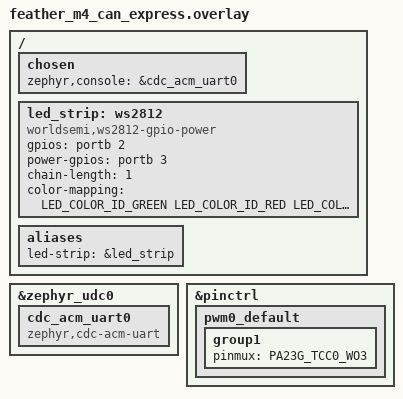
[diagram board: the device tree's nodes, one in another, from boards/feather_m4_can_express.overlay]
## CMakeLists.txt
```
# SPDX-License-Identifier: Apache-2.0

cmake_minimum_required(VERSION 3.20.0)

# Add custom board directory (for feather_m4_can_express)
list(APPEND BOARD_ROOT ${CMAKE_CURRENT_SOURCE_DIR}/..)

# Add custom DTS bindings directory
list(APPEND DTS_ROOT ${CMAKE_CURRENT_SOURCE_DIR})

find_package(Zephyr REQUIRED HINTS $ENV{ZEPHYR_BASE})
project(m4_express_blinky)

target_sources(app PRIVATE
    src/main.c
    src/led.c
    src/canrx.c
    src/canwork.c
    src/pwm.c
    src/ws2812_gpio_sam0.c
)
```

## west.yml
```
# SPDX-License-Identifier: Apache-2.0
#
# West manifest for M4 Express NeoPixel Blinky
# This makes the project a self-contained Zephyr application

manifest:
  remotes:
    - name: zephyrproject-rtos
      url-base: https://github.com/zephyrproject-rtos

  projects:
    - name: zephyr
      remote: zephyrproject-rtos
      revision: main
      import: true

  self:
    path: app
```

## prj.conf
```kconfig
# Logging (immediate mode for USB CDC console)
CONFIG_LOG=y
CONFIG_LOG_MODE_IMMEDIATE=y

# LED Strip driver
CONFIG_LED_STRIP=y
CONFIG_LED_STRIP_LOG_LEVEL_DBG=y

# USB CDC ACM for console
CONFIG_USB_DEVICE_STACK=y
CONFIG_USB_CDC_ACM=y
CONFIG_CONSOLE=y
CONFIG_UART_CONSOLE=y

# USB device identification
CONFIG_USB_DEVICE_PRODUCT="Feather M4 CAN"
CONFIG_USB_DEVICE_VID=0x239A
CONFIG_USB_DEVICE_PID=0x0022

# CAN bus
CONFIG_CAN=y

# PWM
CONFIG_PWM=y

# Increase log buffer for debugging
CONFIG_LOG_BUFFER_SIZE=2048
```

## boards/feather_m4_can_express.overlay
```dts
/*
 * Device tree overlay for Adafruit Feather M4 Express CAN
 * NeoPixel (RGBW) configuration
 *
 * SPDX-License-Identifier: Apache-2.0
 */

#include <zephyr/dt-bindings/led/led.h>
#include <dt-bindings/pinctrl/same51j-pinctrl.h>

/ {
    chosen {
        zephyr,console = &cdc_acm_uart0;
    };

    led_strip: ws2812 {
        compatible = "worldsemi,ws2812-gpio-power";

        /* NeoPixel data pin: PB02 */
        gpios = <&portb 2 0>;

        /* NeoPixel power enable pin: PB03 (set HIGH to power the NeoPixel) */
        power-gpios = <&portb 3 0>;

        chain-length = <1>;

        /* GRBW order for RGBW NeoPixels */
        color-mapping = <LED_COLOR_ID_GREEN
                         LED_COLOR_ID_RED
                         LED_COLOR_ID_BLUE
                         LED_COLOR_ID_WHITE>;
    };

    aliases {
        led-strip = &led_strip;
    };
};

&zephyr_udc0 {
    cdc_acm_uart0: cdc_acm_uart0 {
        compatible = "zephyr,cdc-acm-uart";
    };
};

/* Override PWM0 pinctrl to use LED pin PA23 (TCC0_WO3) */
&pinctrl {
    pwm0_default: pwm0_default {
        group1 {
            pinmux = <PA23G_TCC0_WO3>;
        };
    };
};
```

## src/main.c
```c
/*
 * Main - USB initialization and system startup
 *
 * Adafruit Feather M4 Express CAN Demo
 * - LED thread: cycles NeoPixel through colors
 * - CAN RX thread: receives CAN frames and prints to console
 *
 * SPDX-License-Identifier: Apache-2.0
 */

#include <errno.h>

#define LOG_LEVEL 4
#include <zephyr/logging/log.h>
LOG_MODULE_REGISTER(main);

#include <zephyr/kernel.h>
#include <zephyr/device.h>
#include <zephyr/usb/usb_device.h>

int main(void)
{
	int rc;

	/* Enable USB */
	const struct device *usb_dev = DEVICE_DT_GET_ONE(zephyr_cdc_acm_uart);

	if (!device_is_ready(usb_dev)) {
		LOG_ERR("USB device not ready");
		return 0;
	}

	rc = usb_enable(NULL);
	if (rc != 0 && rc != -EALREADY) {
		LOG_ERR("Failed to enable USB: %d", rc);
		return 0;
	}

	LOG_INF("=== Feather M4 CAN Express Demo ===");
	LOG_INF("LED thread: NeoPixel color cycling");
	LOG_INF("CAN RX thread: listening for CAN frames");
	LOG_INF("CAN work thread: processing received frames");
	LOG_INF("PWM0 thread: PA23/D13 LED duty cycle sweep");
	LOG_INF("PWM1 thread: PA5 duty cycle sweep");

	return 0;
}
```

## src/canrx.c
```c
/*
 * CAN RX Thread - Receives CAN frames and queues for processing
 *
 * SPDX-License-Identifier: Apache-2.0
 */

#define LOG_LEVEL 4
#include <zephyr/logging/log.h>
LOG_MODULE_REGISTER(canrx);

#include <zephyr/kernel.h>
#include <zephyr/device.h>
#include <zephyr/drivers/can.h>
#include <zephyr/drivers/gpio.h>

#include "canwork.h"

/* Thread stack size and priority */
#define CANRX_THREAD_STACK_SIZE 1024
#define CANRX_THREAD_PRIORITY   5

/* CAN device from devicetree */
static const struct device *const can_dev = DEVICE_DT_GET(DT_CHOSEN(zephyr_canbus));

/* CAN transceiver control GPIOs */
static const struct gpio_dt_spec boost_enable = GPIO_DT_SPEC_GET(DT_NODELABEL(boost_enable), gpios);
static const struct gpio_dt_spec can_standby = GPIO_DT_SPEC_GET(DT_NODELABEL(can_standby), gpios);

/* Message queue for frames from CAN driver ISR */
CAN_MSGQ_DEFINE(can_rx_msgq, 16);

/* Statistics */
static volatile uint32_t frames_received;

static int can_transceiver_enable(void)
{
	int ret;

	/* Configure boost enable GPIO (HIGH to enable 5V for CAN bus) */
	if (!gpio_is_ready_dt(&boost_enable)) {
		LOG_ERR("Boost enable GPIO not ready");
		return -ENODEV;
	}


	/* Configure CAN standby GPIO (LOW to enable transceiver) */
	if (!gpio_is_ready_dt(&can_standby)) {
		LOG_ERR("CAN standby GPIO not ready");
		return -ENODEV;
	}

	ret = gpio_pin_configure_dt(&can_standby, GPIO_OUTPUT_LOW);
	if (ret < 0) {
		LOG_ERR("Failed to configure CAN standby: %d", ret);
		return ret;
	}

	ret = gpio_pin_configure_dt(&boost_enable, GPIO_OUTPUT_HIGH);
	if (ret < 0) {
		LOG_ERR("Failed to configure boost enable: %d", ret);
		return ret;
	}

	LOG_INF("CAN transceiver enabled");
	return 0;
}

/*
 * CAN RX thread - receives frames and queues for processing
 */
static void canrx_thread_entry(void *p1, void *p2, void *p3)
{
	ARG_UNUSED(p1);
	ARG_UNUSED(p2);
	ARG_UNUSED(p3);

	struct can_frame frame;
	struct can_filter filter = {
		.flags = 0,
		.id = 0,
		.mask = 0,  /* Accept all IDs */
	};
	int ret;
	int filter_id;

	LOG_INF("CAN RX thread started");

	if (!device_is_ready(can_dev)) {
		LOG_ERR("CAN device not ready");
		return;
	}

	/* Enable the CAN transceiver */
	ret = can_transceiver_enable();
	if (ret < 0) {
		LOG_ERR("Failed to enable CAN transceiver");
		return;
	}

	/* Set CAN bitrate to 500 kbit/s */
	ret = can_set_bitrate(can_dev, 500000);
	if (ret < 0) {
		LOG_ERR("Failed to set CAN bitrate: %d", ret);
		return;
	}

	/* Set listen-only mode (passive - no ACKs or transmissions) */
	ret = can_set_mode(can_dev, CAN_MODE_LISTENONLY);
	if (ret < 0) {
		LOG_ERR("Failed to set CAN mode: %d", ret);
		return;
	}

	/* Start the CAN controller */
	ret = can_start(can_dev);
	if (ret < 0) {
		LOG_ERR("Failed to start CAN: %d", ret);
		return;
	}

	/* Add filter to receive all frames into rx queue */
	filter_id = can_add_rx_filter_msgq(can_dev, &can_rx_msgq, &filter);
	if (filter_id < 0) {
		LOG_ERR("Failed to add CAN filter: %d", filter_id);
		return;
	}

	LOG_INF("CAN initialized, listening for frames...");

	while (1) {
		/* Wait for a frame from the driver */
		ret = k_msgq_get(&can_rx_msgq, &frame, K_FOREVER);
		if (ret == 0) {
			frames_received++;

			/* Submit for processing */
			canwork_submit(&frame);
		}
	}
}

/* Define CAN RX thread statically */
K_THREAD_DEFINE(canrx_thread, CANRX_THREAD_STACK_SIZE,
		canrx_thread_entry, NULL, NULL, NULL,
		CANRX_THREAD_PRIORITY, 0, 0);
```

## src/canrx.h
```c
/*
 * CAN RX Thread Header
 *
 * SPDX-License-Identifier: Apache-2.0
 */

#ifndef CANRX_H_
#define CANRX_H_

/*
 * CAN RX thread is defined statically with K_THREAD_DEFINE and starts
 * automatically at boot. No explicit API needed.
 */

#endif /* CANRX_H_ */
```

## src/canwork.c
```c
/*
 * CAN Work Thread - Processes received CAN frames
 *
 * SPDX-License-Identifier: Apache-2.0
 */

#define LOG_LEVEL 4
#include <zephyr/logging/log.h>
LOG_MODULE_REGISTER(canwork);

#include <zephyr/kernel.h>
#include <zephyr/drivers/can.h>
#include <zephyr/sys/atomic.h>

#include "canwork.h"

/* Thread stack size and priority */
#define CANWORK_THREAD_STACK_SIZE 1024
#define CANWORK_THREAD_PRIORITY   6

/* Work queue depth - frames dropped if full */
#define CAN_WORK_QUEUE_DEPTH 16

/* Message queue for canrx -> canwork communication */
K_MSGQ_DEFINE(can_work_msgq, sizeof(struct can_frame), CAN_WORK_QUEUE_DEPTH, 4);

/* Statistics (atomic for thread-safe access) */
static atomic_t frames_processed;
static atomic_t frames_dropped;

int canwork_submit(const struct can_frame *frame)
{
	int ret;

	ret = k_msgq_put(&can_work_msgq, frame, K_NO_WAIT);
	if (ret != 0) {
		atomic_inc(&frames_dropped);
		LOG_WRN("Work queue full, frame dropped (total dropped: %ld)",
			atomic_get(&frames_dropped));
		return -ENOMSG;
	}

	return 0;
}

uint32_t canwork_get_frames_processed(void)
{
	return (uint32_t)atomic_get(&frames_processed);
}

/*
 * CAN work thread - processes queued frames
 */
static void canwork_thread_entry(void *p1, void *p2, void *p3)
{
	ARG_UNUSED(p1);
	ARG_UNUSED(p2);
	ARG_UNUSED(p3);

	struct can_frame frame;
	int ret;

	LOG_INF("CAN work thread started");

	while (1) {
		/* Wait for a frame to process */
		ret = k_msgq_get(&can_work_msgq, &frame, K_FOREVER);
		if (ret == 0) {
			atomic_val_t count = atomic_inc(&frames_processed) + 1;

			/* Only log every 100th frame to avoid USB bottleneck */
			if ((count % 3) == 1) {
				/* Print the frame */
				if (frame.flags & CAN_FRAME_IDE) {
					LOG_INF("CAN RX: ID=0x%08x [%d] (total: %ld)",
						frame.id, frame.dlc, count);
				} else {
					LOG_INF("CAN RX: ID=0x%03x [%d] (total: %ld)",
						frame.id, frame.dlc, count);
				}
			}
		}
	}
}

/* Define CAN work thread statically */
K_THREAD_DEFINE(canwork_thread, CANWORK_THREAD_STACK_SIZE,
		canwork_thread_entry, NULL, NULL, NULL,
		CANWORK_THREAD_PRIORITY, 0, 0);
```

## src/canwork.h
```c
/*
 * CAN Work Thread Header
 *
 * SPDX-License-Identifier: Apache-2.0
 */

#ifndef CANWORK_H_
#define CANWORK_H_

#include <zephyr/kernel.h>
#include <zephyr/drivers/can.h>

/* Work queue for CAN frames to be processed */
extern struct k_msgq can_work_msgq;

/*
 * Submit a CAN frame for processing.
 * Non-blocking - returns 0 on success, -ENOMSG if queue is full (frame dropped).
 */
int canwork_submit(const struct can_frame *frame);

/*
 * Get the number of CAN frames processed.
 */
uint32_t canwork_get_frames_processed(void);

#endif /* CANWORK_H_ */
```

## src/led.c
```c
/*
 * LED Thread - NeoPixel color cycling based on CAN frames
 *
 * SPDX-License-Identifier: Apache-2.0
 */

#include <string.h>

#define LOG_LEVEL 4
#include <zephyr/logging/log.h>
LOG_MODULE_REGISTER(led);

#include <zephyr/kernel.h>
#include <zephyr/drivers/led_strip.h>
#include <zephyr/device.h>
#include <zephyr/sys/util.h>

#include "canwork.h"

#define STRIP_NUM_PIXELS 1

/* LED thread stack size and priority (lowest priority) */
#define LED_THREAD_STACK_SIZE 1024
#define LED_THREAD_PRIORITY   K_LOWEST_APPLICATION_THREAD_PRIO

#define RGB(_r, _g, _b) { .r = (_r), .g = (_g), .b = (_b) }

static const struct led_rgb colors[] = {
	RGB(0x20, 0x00, 0x00), /* red */
	RGB(0x00, 0x20, 0x00), /* green */
	RGB(0x00, 0x00, 0x20), /* blue */
	RGB(0x20, 0x20, 0x20), /* white (RGB mix) */
};

static struct led_rgb pixels[STRIP_NUM_PIXELS];

static const struct device *const strip = DEVICE_DT_GET(DT_NODELABEL(led_strip));

/*
 * LED flashing thread - runs at lowest priority
 * This thread handles the LED color cycling independently
 */
static void led_thread_entry(void *p1, void *p2, void *p3)
{
	ARG_UNUSED(p1);
	ARG_UNUSED(p2);
	ARG_UNUSED(p3);

	size_t color = 0;
	int rc;

	LOG_INF("LED thread started (priority: %d)", LED_THREAD_PRIORITY);

	if (!device_is_ready(strip)) {
		LOG_ERR("LED strip device %s is NOT ready", strip->name);
		return;
	}

	LOG_INF("LED strip device is ready");
	LOG_INF("Starting color cycle based on CAN frames received");

	while (1) {
		/* Select color based on CAN frames received mod 4 */
		color = canwork_get_frames_processed() % ARRAY_SIZE(colors);

		memset(&pixels, 0x00, sizeof(pixels));
		memcpy(&pixels[0], &colors[color], sizeof(struct led_rgb));

		rc = led_strip_update_rgb(strip, pixels, STRIP_NUM_PIXELS);
		if (rc) {
			LOG_ERR("led_strip_update_rgb failed: %d", rc);
		}

		k_sleep(K_MSEC(50));
	}
}

/* Define LED thread statically - starts automatically at boot */
K_THREAD_DEFINE(led_thread, LED_THREAD_STACK_SIZE,
		led_thread_entry, NULL, NULL, NULL,
		LED_THREAD_PRIORITY, 0, 0);
```

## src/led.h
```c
/*
 * LED Thread Header
 *
 * SPDX-License-Identifier: Apache-2.0
 */

#ifndef LED_H_
#define LED_H_

/*
 * LED thread is defined statically with K_THREAD_DEFINE and starts
 * automatically at boot. No explicit API needed.
 */

#endif /* LED_H_ */
```

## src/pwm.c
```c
/*
 * PWM Threads - Hardware PWM control on two pins
 *
 * PWM0: TCC0 channel 2 on PA22
 * PWM1: TC0 channel 1 on PA5
 *
 * Both cycle through 0%, 50%, 100% duty cycle (5 seconds each)
 *
 * SPDX-License-Identifier: Apache-2.0
 */

#define LOG_LEVEL 4
#include <zephyr/logging/log.h>
LOG_MODULE_REGISTER(pwm);

#include <zephyr/kernel.h>
#include <zephyr/device.h>
#include <zephyr/drivers/pwm.h>

/* PWM thread stack size and priority */
#define PWM_THREAD_STACK_SIZE 1024
#define PWM_THREAD_PRIORITY   8

/* PWM period (1 kHz = 1ms period) */
#define PWM_PERIOD_NS 1000000U

/* Duty cycle hold time */
#define DUTY_HOLD_MS 5000

/* PWM configuration structure - device resolved at runtime */
struct pwm_config {
	const char *dev_label;
	uint32_t channel;
	const char *name;
};

/* PWM configurations - device lookup done at runtime */
static const struct pwm_config pwm_configs[] = {
	{
		.dev_label = "pwm_0",  /* DT alias */
		.channel = 3,         /* TCC0_WO3 on PA23 (LED) */
		.name = "PWM0",
	},
	{
		.dev_label = "pwm_1",  /* DT alias */
		.channel = 1,         /* TC0_WO1 */
		.name = "PWM1",
	},
};

/* Duty cycle percentages to cycle through */
static const uint8_t duty_cycles[] = { 0, 50, 100 };

/*
 * PWM thread entry point - shared by both PWM threads
 * p1: index into pwm_configs
 */
static void pwm_thread_entry(void *p1, void *p2, void *p3)
{
	int cfg_idx = (int)(intptr_t)p1;
	ARG_UNUSED(p2);
	ARG_UNUSED(p3);

	const struct pwm_config *cfg = &pwm_configs[cfg_idx];
	const struct device *dev;
	size_t idx = 0;
	int ret;

	LOG_INF("%s thread started", cfg->name);

	/* Get PWM device at runtime */
	if (cfg_idx == 0) {
		dev = DEVICE_DT_GET(DT_ALIAS(pwm_0));
	} else {
		dev = DEVICE_DT_GET(DT_ALIAS(pwm_1));
	}

	if (dev == NULL) {
		LOG_ERR("%s: PWM device is NULL", cfg->name);
		return;
	}

	if (!device_is_ready(dev)) {
		LOG_ERR("%s: PWM device not ready", cfg->name);
		return;
	}

	LOG_INF("%s: PWM device ready (channel %u), period=%u ns",
		cfg->name, cfg->channel, PWM_PERIOD_NS);

	while (1) {
		uint8_t duty_pct = duty_cycles[idx];
		uint32_t pulse_ns = (PWM_PERIOD_NS * duty_pct) / 100;

		ret = pwm_set(dev, cfg->channel, PWM_PERIOD_NS, pulse_ns, 0);
		if (ret < 0) {
			LOG_ERR("%s: pwm_set failed: %d", cfg->name, ret);
		} else {
			LOG_INF("%s: duty=%3u%% (pulse=%u ns)",
				cfg->name, duty_pct, pulse_ns);
		}

		k_sleep(K_MSEC(DUTY_HOLD_MS));

		idx = (idx + 1) % ARRAY_SIZE(duty_cycles);
	}
}

/* Define PWM threads statically - delayed start (1000ms) to let system stabilize */
K_THREAD_DEFINE(pwm0_thread, PWM_THREAD_STACK_SIZE,
		pwm_thread_entry, (void *)0, NULL, NULL,
		PWM_THREAD_PRIORITY, 0, 1000);

/* TEMPORARILY DISABLED FOR DEBUGGING
K_THREAD_DEFINE(pwm1_thread, PWM_THREAD_STACK_SIZE,
		pwm_thread_entry, (void *)1, NULL, NULL,
		PWM_THREAD_PRIORITY, 0, 0);
*/
```

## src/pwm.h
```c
/*
 * PWM Threads Header
 *
 * SPDX-License-Identifier: Apache-2.0
 */

#ifndef PWM_H_
#define PWM_H_

/*
 * PWM threads are defined statically with K_THREAD_DEFINE and start
 * automatically at boot. No explicit API needed.
 */

#endif /* PWM_H_ */
```

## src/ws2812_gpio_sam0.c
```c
/*
 * WS2812 GPIO driver for SAM0 (SAMD51, etc.)
 *
 * Bit-banged WS2812/NeoPixel driver optimized for SAMD51 at 120 MHz.
 * Based on the nRF GPIO driver, adapted for SAM0 register layout and timing.
 *
 * Features:
 *   - Direct register access for precise timing
 *   - Optional power GPIO support (for boards like Feather M4 CAN)
 *   - Automatic PMUX disable for GPIO mode
 *
 * SPDX-License-Identifier: Apache-2.0
 */

#include <zephyr/drivers/led_strip.h>
#include <string.h>

#define LOG_LEVEL CONFIG_LED_STRIP_LOG_LEVEL
#include <zephyr/logging/log.h>
LOG_MODULE_REGISTER(ws2812_gpio_sam0);

#include <zephyr/kernel.h>
#include <soc.h>
#include <zephyr/drivers/gpio.h>
#include <zephyr/device.h>
#include <zephyr/dt-bindings/led/led.h>

/* Check if this is a SAM0 device */
#if !defined(PORT) && !defined(PortGroup)
#error "This driver is only for SAM0 devices (SAMD51, etc.)"
#endif

struct ws2812_gpio_sam0_cfg {
	struct gpio_dt_spec gpio;
	struct gpio_dt_spec power_gpio;
	bool has_power_gpio;
	uint8_t num_colors;
	const uint8_t *color_mapping;
	size_t length;
};

/*
 * SAM0 GPIO register layout for PortGroup:
 *   OUTCLR at offset 0x14
 *   OUTSET at offset 0x18
 *
 * We use OUTCLR as base, so:
 *   base + 0 = OUTCLR (set low)
 *   base + 4 = OUTSET (set high)
 */
#define SET_HIGH "str %[p], [%[r], #4]\n"
#define SET_LOW "str %[p], [%[r], #0]\n"

/*
 * Timing for WS2812 at 120 MHz (SAMD51):
 * Each NOP = 1 cycle = 8.33ns
 *
 * WS2812 timing requirements (from datasheet):
 *   T0H: 400ns ± 150ns  -> target ~48 cycles
 *   T0L: 850ns ± 150ns  -> target ~102 cycles
 *   T1H: 800ns ± 150ns  -> target ~96 cycles
 *   T1L: 450ns ± 150ns  -> target ~54 cycles
 */
#ifndef WS2812_SAM0_DELAY_T1H
#define WS2812_SAM0_DELAY_T1H 90
#endif
#ifndef WS2812_SAM0_DELAY_T1L
#define WS2812_SAM0_DELAY_T1L 45
#endif
#ifndef WS2812_SAM0_DELAY_T0H
#define WS2812_SAM0_DELAY_T0H 40
#endif
#ifndef WS2812_SAM0_DELAY_T0L
#define WS2812_SAM0_DELAY_T0L 95
#endif

#define NOPS(i, _) "nop\n"
#define NOP_N_TIMES(n) LISTIFY(n, NOPS, ())

/* Send out a 1 bit's pulse */
#define ONE_BIT(base, pin) do {                     \
	__asm volatile (SET_HIGH                    \
			NOP_N_TIMES(WS2812_SAM0_DELAY_T1H)   \
			SET_LOW                         \
			NOP_N_TIMES(WS2812_SAM0_DELAY_T1L)   \
			::                              \
			[r] "l" (base),                 \
			[p] "l" (pin)); } while (false)

/* Send out a 0 bit's pulse */
#define ZERO_BIT(base, pin) do {                    \
	__asm volatile (SET_HIGH                    \
			NOP_N_TIMES(WS2812_SAM0_DELAY_T0H)   \
			SET_LOW                         \
			NOP_N_TIMES(WS2812_SAM0_DELAY_T0L)   \
			::                              \
			[r] "l" (base),                 \
			[p] "l" (pin)); } while (false)

/*
 * Get PortGroup pointer for a given GPIO port device.
 */
static inline PortGroup *get_port_group(const struct device *gpio_dev)
{
	const char *name = gpio_dev->name;

	if (name[4] == 'a' || name[4] == 'A') {
		return &PORT->Group[0];
	} else if (name[4] == 'b' || name[4] == 'B') {
		return &PORT->Group[1];
	} else if (name[4] == 'c' || name[4] == 'C') {
		return &PORT->Group[2];
	} else if (name[4] == 'd' || name[4] == 'D') {
		return &PORT->Group[3];
	}

	return &PORT->Group[1];
}

static int send_buf(const struct ws2812_gpio_sam0_cfg *config,
		    uint8_t *buf, size_t len)
{
	PortGroup *port = get_port_group(config->gpio.port);
	volatile uint32_t *base = &port->OUTCLR.reg;
	const uint32_t val = BIT(config->gpio.pin);
	unsigned int key;

	port->OUTCLR.reg = val;
	k_busy_wait(80);

	key = irq_lock();

	while (len--) {
		uint32_t b = *buf++;
		int32_t i;

		for (i = 7; i >= 0; i--) {
			if (b & BIT(i)) {
				ONE_BIT(base, val);
			} else {
				ZERO_BIT(base, val);
			}
		}
	}

	irq_unlock(key);
	port->OUTCLR.reg = val;

	return 0;
}

static int ws2812_gpio_sam0_update_rgb(const struct device *dev,
				       struct led_rgb *pixels,
				       size_t num_pixels)
{
	const struct ws2812_gpio_sam0_cfg *config = dev->config;
	uint8_t *ptr = (uint8_t *)pixels;
	size_t i;

	for (i = 0; i < num_pixels; i++) {
		uint8_t j;
		const struct led_rgb current_pixel = pixels[i];

		for (j = 0; j < config->num_colors; j++) {
			switch (config->color_mapping[j]) {
			case LED_COLOR_ID_WHITE:
				*ptr++ = 0;
				break;
			case LED_COLOR_ID_RED:
				*ptr++ = current_pixel.r;
				break;
			case LED_COLOR_ID_GREEN:
				*ptr++ = current_pixel.g;
				break;
			case LED_COLOR_ID_BLUE:
				*ptr++ = current_pixel.b;
				break;
			default:
				return -EINVAL;
			}
		}
	}

	return send_buf(config, (uint8_t *)pixels, num_pixels * config->num_colors);
}

static size_t ws2812_gpio_sam0_length(const struct device *dev)
{
	const struct ws2812_gpio_sam0_cfg *config = dev->config;

	return config->length;
}

static const struct led_strip_driver_api ws2812_gpio_sam0_api = {
	.update_rgb = ws2812_gpio_sam0_update_rgb,
	.length = ws2812_gpio_sam0_length,
};

static int ws2812_gpio_sam0_init(const struct device *dev)
{
	const struct ws2812_gpio_sam0_cfg *cfg = dev->config;
	PortGroup *port;
	PortGroup *power_port;
	uint8_t i;
	uint8_t pin = cfg->gpio.pin;
	int ret;

	/*
	 * Enable power to the NeoPixel if power-gpios is defined.
	 * Required on boards like Feather M4 CAN where the NeoPixel
	 * has a separate power control pin.
	 */
	if (cfg->has_power_gpio) {
		if (!gpio_is_ready_dt(&cfg->power_gpio)) {
			LOG_ERR("Power GPIO device not ready");
			return -ENODEV;
		}

		power_port = get_port_group(cfg->power_gpio.port);
		power_port->PINCFG[cfg->power_gpio.pin].reg &= ~PORT_PINCFG_PMUXEN;

		ret = gpio_pin_configure_dt(&cfg->power_gpio, GPIO_OUTPUT_HIGH);
		if (ret < 0) {
			LOG_ERR("Failed to configure power GPIO: %d", ret);
			return ret;
		}

		LOG_INF("NeoPixel power enabled on port %s pin %d",
			cfg->power_gpio.port->name, cfg->power_gpio.pin);

		k_msleep(10);
	}

	if (!gpio_is_ready_dt(&cfg->gpio)) {
		LOG_ERR("GPIO device not ready");
		return -ENODEV;
	}

	for (i = 0; i < cfg->num_colors; i++) {
		switch (cfg->color_mapping[i]) {
		case LED_COLOR_ID_WHITE:
		case LED_COLOR_ID_RED:
		case LED_COLOR_ID_GREEN:
		case LED_COLOR_ID_BLUE:
			break;
		default:
			LOG_ERR("%s: invalid channel to color mapping", dev->name);
			return -EINVAL;
		}
	}

	port = get_port_group(cfg->gpio.port);

	/*
	 * Clear PMUXEN to disconnect pin from any peripheral (SERCOM, etc.)
	 * and enable GPIO mode.
	 */
	port->PINCFG[pin].reg &= ~PORT_PINCFG_PMUXEN;

	ret = gpio_pin_configure_dt(&cfg->gpio, GPIO_OUTPUT_LOW);
	if (ret < 0) {
		LOG_ERR("Failed to configure GPIO: %d", ret);
		return ret;
	}

	port->DIRSET.reg = BIT(pin);
	port->OUTCLR.reg = BIT(pin);

	LOG_INF("WS2812 SAM0 GPIO driver initialized on port %s pin %d",
		cfg->gpio.port->name, pin);

	return 0;
}

/* Color mapping for RGBW NeoPixels (GRBW wire order) */
static const uint8_t ws2812_sam0_color_mapping[] = {
	LED_COLOR_ID_GREEN,
	LED_COLOR_ID_RED,
	LED_COLOR_ID_BLUE,
	LED_COLOR_ID_WHITE,
};

#define HAS_POWER_GPIO DT_NODE_HAS_PROP(DT_NODELABEL(led_strip), power_gpios)

static const struct ws2812_gpio_sam0_cfg ws2812_gpio_sam0_cfg = {
	.gpio = GPIO_DT_SPEC_GET(DT_NODELABEL(led_strip), gpios),
#if HAS_POWER_GPIO
	.power_gpio = GPIO_DT_SPEC_GET(DT_NODELABEL(led_strip), power_gpios),
	.has_power_gpio = true,
#else
	.has_power_gpio = false,
#endif
	.num_colors = 4,
	.color_mapping = ws2812_sam0_color_mapping,
	.length = DT_PROP(DT_NODELABEL(led_strip), chain_length),
};

DEVICE_DT_DEFINE(DT_NODELABEL(led_strip),
		 ws2812_gpio_sam0_init,
		 NULL,
		 NULL,
		 &ws2812_gpio_sam0_cfg,
		 POST_KERNEL,
		 CONFIG_LED_STRIP_INIT_PRIORITY,
		 &ws2812_gpio_sam0_api);
```
